VERSION ""
NS_ :

BS_:
BU_:
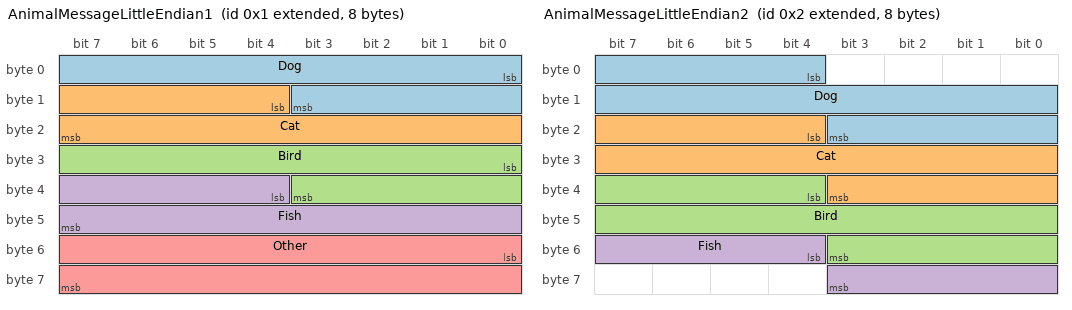
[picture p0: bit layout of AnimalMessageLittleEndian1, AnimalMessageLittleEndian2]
BO_ 2147483649 AnimalMessageLittleEndian1: 8 Vector__XXX
 SG_ Dog : 0|12@1+ (1,0) [0|4095] "dog" Vector__XXX
 SG_ Cat : 12|12@1+ (1,0) [0|4095] "cat" Vector__XXX
 SG_ Bird : 24|12@1+ (1,0) [0|4095] "bird" Vector__XXX
 SG_ Fish : 36|12@1+ (1,0) [0|4095] "fish" Vector__XXX
 SG_ Other : 48|16@1+ (1,0) [0|4095] "other" Vector__XXX

BO_ 2147483650 AnimalMessageLittleEndian2: 8 Vector__XXX
 SG_ Dog : 4|16@1+ (1,0) [0|4095] "dog" Vector__XXX
 SG_ Cat : 20|16@1+ (1,0) [0|4095] "cat" Vector__XXX
 SG_ Bird : 36|16@1+ (1,0) [0|4095] "bird" Vector__XXX
 SG_ Fish : 52|8@1+ (1,0) [0|4095] "fish" Vector__XXX

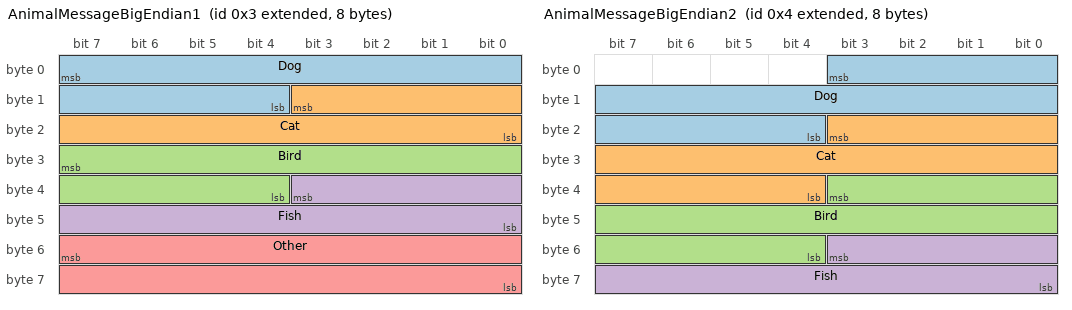
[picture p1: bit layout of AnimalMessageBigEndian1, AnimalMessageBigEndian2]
BO_ 2147483651 AnimalMessageBigEndian1: 8 Vector__XXX
 SG_ Dog : 7|12@0+ (1,0) [0|4095] "dog" Vector__XXX
 SG_ Cat : 11|12@0+ (1,0) [0|4095] "cat" Vector__XXX
 SG_ Bird : 31|12@0+ (1,0) [0|4095] "bird" Vector__XXX
 SG_ Fish : 35|12@0+ (1,0) [0|4095] "fish" Vector__XXX
 SG_ Other : 55|16@0+ (1,0) [0|4095] "other" Vector__XXX

BO_ 2147483652 AnimalMessageBigEndian2: 8 Vector__XXX
 SG_ Dog : 3|16@0+ (1,0) [0|4095] "dog" Vector__XXX
 SG_ Cat : 19|16@0+ (1,0) [0|4095] "cat" Vector__XXX
 SG_ Bird : 35|16@0+ (1,0) [0|4095] "bird" Vector__XXX
 SG_ Fish : 51|12@0+ (1,0) [0|4095] "fish" Vector__XXX
